VERSION ""

NS_ :

BS_:
BU_:
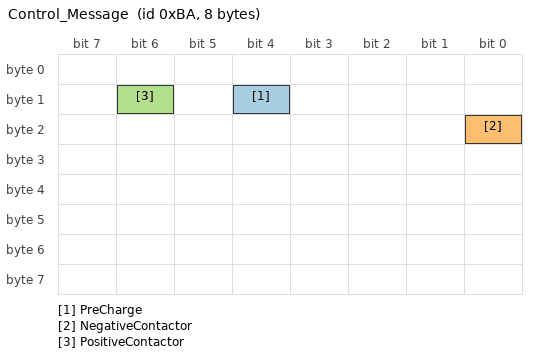
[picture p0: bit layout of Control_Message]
BO_ 186 Control_Message: 8 Vector__XXX
   SG_ PreCharge : 12|1@1+ (1,0) [0|0] "" Vector__XXX
   SG_ NegativeContactor : 16|1@1+ (1,0) [0|0] "" Vector__XXX
   SG_ PositiveContactor : 14|1@1+ (1,0) [0|0] "" Vector__XXX

BA_DEF_ BO_ "GenMsgBackgroundColor" STRING ;
BA_DEF_ BO_ "GenMsgForegroundColor" STRING ;
BA_DEF_DEF_ "GenMsgBackgroundColor" "#ffffff";
BA_DEF_DEF_ "GenMsgForegroundColor" "#000000";
VAL_ 186 PreCharge 0 "Off" 1 "On";
VAL_ 186 NegativeContactor 0 "Off" 1 "On";
VAL_ 186 PositiveContactor 0 "Off" 1 "On";
